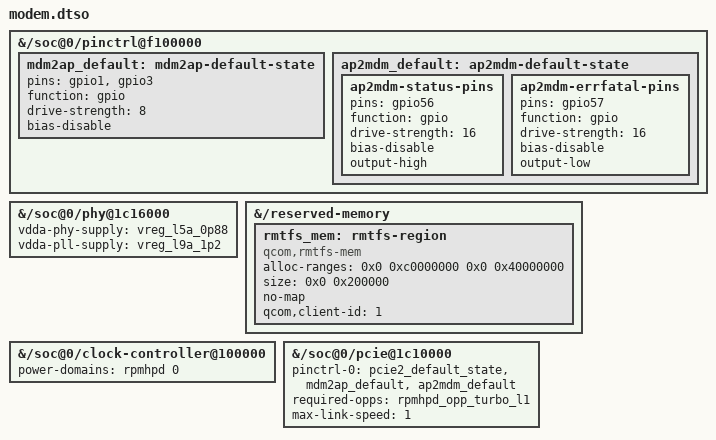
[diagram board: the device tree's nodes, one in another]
// SPDX-License-Identifier: MIT
/*
 * Bring-up overlay (MODEM-PLAN Phase 1): enable PCIe2 and its QMP modem PHY
 * for the external SDX55M cellular modem (qcom,ext-sdx55m) on Galaxy S20 FE (r8q).
 *
 * sm8250.dtsi already configures &pcie2 with perst-gpios (GPIO 85), wake-gpios
 * (GPIO 87), and pcie2_default_state (CLKREQ GPIO 86). Stock live.dts and
 * upstream sm8250-sony-xperia-edo.dtsi add mdm2ap (GPIO 1, 3) and ap2mdm
 * (GPIO 56, 57) pinmuxes and vreg_l5a_0p88 / vreg_l9a_1p2 on &pcie2_phy.
 */
/dts-v1/;
/plugin/;

&{/soc@0/pinctrl@f100000} {
	mdm2ap_default: mdm2ap-default-state {
		pins = "gpio1", "gpio3";
		function = "gpio";
		drive-strength = <8>;
		bias-disable;
	};

	/*
	 * AP2MDM_STATUS (gpio56) must read HIGH before the modem boots:
	 * stock's modem driver asserts it as "AP alive", and with it low
	 * the SDX55M stays in SBL after its SAHARA image set instead of
	 * jumping to AMSS. AP2MDM_ERRFATAL (gpio57) stays LOW (no error).
	 * Driving them from this pinctrl state puts them in place at
	 * PCIe2 probe, before the link comes up (the reference port for
	 * this flashless-modem setup does the same).
	 */
	ap2mdm_default: ap2mdm-default-state {
		ap2mdm-status-pins {
			pins = "gpio56";
			function = "gpio";
			drive-strength = <16>;
			bias-disable;
			output-high;
		};

		ap2mdm-errfatal-pins {
			pins = "gpio57";
			function = "gpio";
			drive-strength = <16>;
			bias-disable;
			output-low;
		};
	};
};

&{/soc@0/phy@1c16000} {
	vdda-phy-supply = <&vreg_l5a_0p88>;
	vdda-pll-supply = <&vreg_l9a_1p2>;
	status = "okay";
};

/*
 * Stock votes VDD_CX to its maximum while PCIe runs: every PCIe node has
 * vreg-cx-supply and qcom,vreg-cx-voltage-level = <0xffff 0x100 0x0>.
 * Mainline has no vreg-cx property. The equivalent is the RPMHPD CX
 * domain plus required-opps, as sc8280xp does: GCC attaches CX (its
 * GDSCs become CX subdomains) and pcie2's GDSC performance state
 * propagates up to CX. dev_pm_domain_attach() only attaches the first
 * power domain, so CX must come in through GCC, not through pcie2.
 */
/*
 * The flashless SDX55M reads and writes its EFS through a host DRAM
 * window: rmtfs maps /dev/qcom_rmtfs_mem1 (created by the
 * qcom,rmtfs-mem driver from this region) and hands the physical
 * address to the modem over QMI, and the modem DMAs through PCIe.
 * The address is negotiated, not fixed, so allocate the region
 * dynamically from free System RAM (0xc0000000 is free per
 * /proc/iomem; stock's low map has no hole to reuse).
 */
&{/reserved-memory} {
	rmtfs_mem: rmtfs-region {
		compatible = "qcom,rmtfs-mem";
		alloc-ranges = <0x0 0xc0000000 0x0 0x40000000>;
		size = <0x0 0x200000>;
		no-map;

		qcom,client-id = <1>;
	};
};

&{/soc@0/clock-controller@100000} {
	/* RPMHPD_CX = 0, dt-bindings/power/qcom,rpmhpd.h */
	power-domains = <&rpmhpd 0>;
};

&{/soc@0/pcie@1c10000} {
	pinctrl-0 = <&pcie2_default_state &mdm2ap_default &ap2mdm_default>;
	status = "okay";
	/*
	 * The SBL image set moves at Gen3 x2, but the AMSS jump then trips
	 * CmpltTO/RxErr and the link dies. Gen2 (5 GT/s) and Gen1 (2.5
	 * GT/s) failed the same way, so the speed cap is not the cause.
	 * Stock's CX vote is the remaining software difference; ask for
	 * the top CX corner (rpmhpd clamps to what the rail supports) and
	 * keep Gen1 until the link survives the AMSS jump.
	 */
	required-opps = <&rpmhpd_opp_turbo_l1>;
	max-link-speed = <1>;
};
